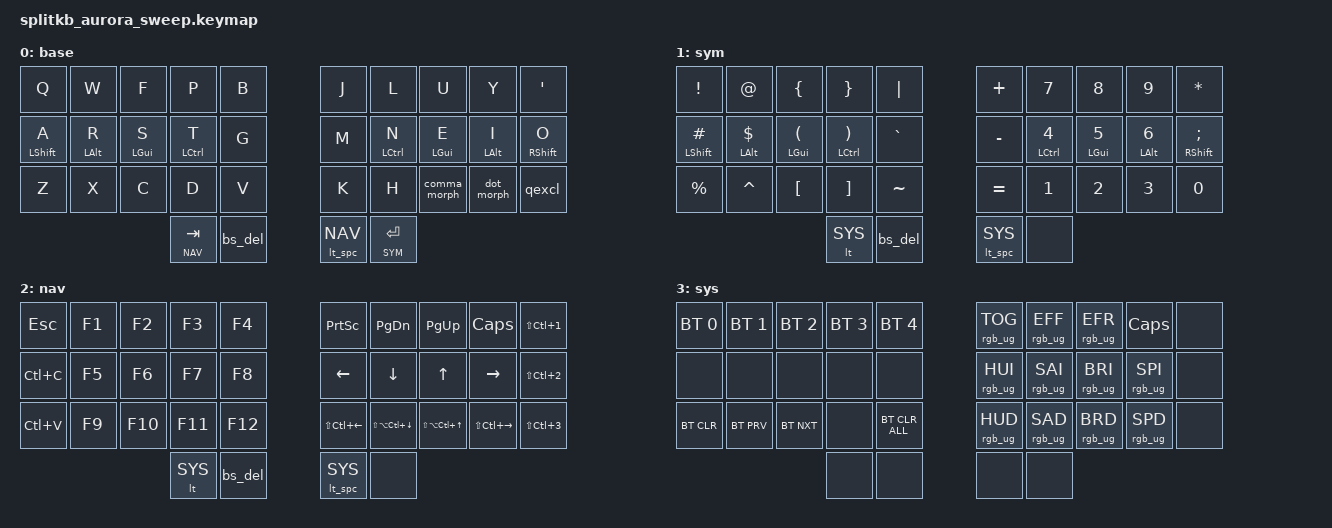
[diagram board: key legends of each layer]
#include <behaviors.dtsi>
#include <dt-bindings/zmk/bt.h>
#include <dt-bindings/zmk/keys.h>
#include <dt-bindings/zmk/rgb.h>

#include "zmk-helpers/helper.h"
#include "zmk-helpers/key-labels/34.h"

#define BASE 0
#define SYM 1
#define NAV 2
#define SYS 3

// #include "mouse.dtsi"

#define XXX &none
#define ___ &trans

#define QUICK_TAP_MS 175

&led_strip {
    chain-length = <23>;
};

&sk {  // sticky-key config
    release-after-ms = <900>;  // release after 0.6s
    quick-release;             // no double capitalization when rolling keys
};

&sl {  // sticky-layer config
    ignore-modifiers;          // allow chording sticky mods & layers
};

&lt {  // layer-tap config
    flavor = "balanced";
    tapping-term-ms = <200>;
    quick-tap-ms = <QUICK_TAP_MS>;
};

/* Homerow mods */
#define KEYS_L LT0 LT1 LT2 LT3 LT4 LM0 LM1 LM2 LM3 LM4 LB0 LB1 LB2 LB3 LB4  // left-hand keys
#define KEYS_R RT0 RT1 RT2 RT3 RT4 RM0 RM1 RM2 RM3 RM4 RB0 RB1 RB2 RB3 RB4  // right-hand keys
#define THUMBS LH1 LH0 RH0 RH1                                              // thumb keys

#define MAKE_HRM(NAME, HOLD, TAP, TRIGGER_POS) \
    ZMK_HOLD_TAP(NAME, \
        flavor = "balanced"; \
        tapping-term-ms = <280>; \
        quick-tap-ms = <QUICK_TAP_MS>; \
        require-prior-idle-ms = <150>; \
        bindings = <HOLD>, <TAP>; \
        hold-trigger-key-positions = <TRIGGER_POS>; \
        hold-trigger-on-release; \
    )

MAKE_HRM(hml, &kp, &kp, KEYS_R THUMBS)  // left-hand HRMs
MAKE_HRM(hmr, &kp, &kp, KEYS_L THUMBS)  // right-hand HRMs

/* Custom behaviors */

// reuse basic mod-morph scheme
#define SIMPLE_MORPH(NAME, MOD, BINDING1, BINDING2) \
    ZMK_MOD_MORPH(NAME, \
        mods = <(MOD_L ## MOD|MOD_R ## MOD)>; \
        bindings = <BINDING1>, <BINDING2>; \
    )

// tap: space | shift + tap: dot -> space -> sticky shift | hold: activate layer
ZMK_HOLD_TAP(lt_spc,
    flavor = "balanced";
    tapping-term-ms = <200>;
    quick-tap-ms = <QUICK_TAP_MS>;
    bindings = <&mo>, <&spc_morph>;
)
SIMPLE_MORPH(spc_morph, SFT, &kp SPACE, &dot_spc)
ZMK_MACRO(dot_spc,
    wait-ms = <0>;
    tap-ms = <5>;
    bindings = <&kp DOT &kp SPACE &sk LSHFT>;
)

// tap: comma | shift + tap: semicolon | ctrl + shift + tap: <
SIMPLE_MORPH(comma_morph, SFT, &kp COMMA, &comma_inner_morph)
SIMPLE_MORPH(comma_inner_morph, CTL, &kp SEMICOLON, &kp LESS_THAN)

// tap: dot | shift + tap: colon | ctrl + shift + tap: >
SIMPLE_MORPH(dot_morph, SFT, &kp DOT, &dot_inner_morph)
SIMPLE_MORPH(dot_inner_morph, CTL, &kp COLON, &kp GREATER_THAN)

// tap: qmark | shift + tap: excl
SIMPLE_MORPH(qexcl, SFT, &kp QMARK, &kp EXCL)

// // tap: copy | double-tap: cut
// ZMK_TAP_DANCE(copy_cut, tap_dance,
//     tapping-term-ms = <200>;
//     bindings = <&kp LC(INS)>, <&kp LC(X)>;
// )

// tap: backspace | lshft + tap: delete | rshft + tap: shift-delete
ZMK_MOD_MORPH(bs_del,
    bindings = <&kp BSPC>, <&kp DEL>;
    mods = <(MOD_LSFT|MOD_RSFT)>;
    keep-mods = <MOD_RSFT>;
)

// Keybind aliases
#define MOVETO_1 &kp LS(LC(N1))
#define MOVETO_2 &kp LS(LC(N2))
#define MOVETO_3 &kp LS(LC(N3))

#define TERM_LEFT   &kp LS(LC(LEFT))
#define TERM_RIGHT   &kp LS(LC(RIGHT))

#define WRKSPC_DN &kp LS(LA(LC(DOWN)))
#define WRKSPC_UP &kp LS(LA(LC(UP)))

ZMK_LAYER(base,
//╭─────────────┬─────────────┬─────────────┬─────────────┬─────────────╮ ╭─────────────┬─────────────┬─────────────┬─────────────┬─────────────╮
    &kp Q         &kp W         &kp F         &kp P         &kp B           &kp J         &kp L         &kp U         &kp Y         &kp SQT
//├─────────────┼─────────────┼─────────────┼─────────────┼─────────────┤ ├─────────────┼─────────────┼─────────────┼─────────────┼─────────────┤
    &hml LSHFT A    &hml LALT R     &hml LGUI S     &hml LCTRL T     &kp G           &kp M         &hmr LCTRL N     &hmr LGUI  E    &hmr LALT I &hmr RSHFT O
//├─────────────┼─────────────┼─────────────┼─────────────┼─────────────┤ ├─────────────┼─────────────┼─────────────┼─────────────┼─────────────┤
    &kp Z         &kp X         &kp C         &kp D         &kp V           &kp K         &kp H         &comma_morph  &dot_morph    &qexcl
//╰─────────────┼─────────────┴─────────────┼─────────────┼─────────────┤ ├─────────────┼─────────────┼─────────────┴───────────────────────────╯
                                              &lt NAV TAB   &bs_del         &lt_spc NAV   &lt SYM RET
//                                          ╰─────────────┴─────────────╯ ╰─────────────┴─────────────╯
)

ZMK_LAYER(sym,
//╭─────────────┬─────────────┬─────────────┬─────────────┬─────────────╮ ╭─────────────┬─────────────┬─────────────┬─────────────┬─────────────╮
    &kp EXCL      &kp AT_SIGN &kp LEFT_BRACE &kp RIGHT_BRACE &kp PIPE       &kp PLUS      &kp N7        &kp N8        &kp N9        &kp ASTERISK
//├─────────────┼─────────────┼─────────────┼─────────────┼─────────────┤ ├─────────────┼─────────────┼─────────────┼─────────────┼─────────────┤
    &hml LSHFT HASH &hml LALT DOLLAR &hml LGUI LPAR &hml LCTRL RPAR  &kp GRAVE  &kp MINUS &hmr LCTRL N4  &hmr LGUI N5    &hmr LALT N6    &hmr RSHFT SEMICOLON
//├─────────────┼─────────────┼─────────────┼─────────────┼─────────────┤ ├─────────────┼─────────────┼─────────────┼─────────────┼─────────────┤
    &kp PERCENT   &kp CARET   &kp LEFT_BRACKET &kp RIGHT_BRACKET &kp TILDE  &kp EQUAL     &kp N1        &kp N2        &kp N3        &kp N0
//╰─────────────┼─────────────┴─────────────┼─────────────┼─────────────┤ ├─────────────┼─────────────┼─────────────┴───────────────────────────╯
                                              &lt SYS       &bs_del         &lt_spc SYS   XXX
//                                          ╰─────────────┴─────────────╯ ╰─────────────┴─────────────╯
)

ZMK_LAYER(nav,
//╭─────────────┬─────────────┬─────────────┬─────────────┬─────────────╮ ╭─────────────┬─────────────┬─────────────┬─────────────┬─────────────╮
    &kp ESC       &kp F1         &kp F2       &kp F3        &kp F4        &kp PRINTSCREEN &kp PAGE_DOWN &kp PAGE_UP   &kp CAPSLOCK  MOVETO_1
//├─────────────┼─────────────┼─────────────┼─────────────┼─────────────┤ ├─────────────┼─────────────┼─────────────┼─────────────┼─────────────┤
    &kp LC(C)     &kp F5         &kp F6       &kp F7        &kp F8          &kp LEFT      &kp DOWN      &kp UP        &kp RIGHT     MOVETO_2
//├─────────────┼─────────────┼─────────────┼─────────────┼─────────────┤ ├─────────────┼─────────────┼─────────────┼─────────────┼─────────────┤
    &kp LC(V)     &kp F9         &kp F10      &kp F11       &kp F12         TERM_LEFT     WRKSPC_DN     WRKSPC_UP     TERM_RIGHT    MOVETO_3
//╰─────────────┼─────────────┴─────────────┼─────────────┼─────────────┤ ├─────────────┼─────────────┼─────────────┴───────────────────────────╯
                                              &lt SYS       &bs_del         &lt_spc SYS   XXX
//                                          ╰─────────────┴─────────────╯ ╰─────────────┴─────────────╯
)

ZMK_LAYER(sys,
//╭─────────────┬─────────────┬─────────────┬─────────────┬─────────────╮ ╭─────────────┬─────────────┬─────────────┬─────────────┬─────────────╮
    &bt BT_SEL 0  &bt BT_SEL 1  &bt BT_SEL 2  &bt BT_SEL 3  &bt BT_SEL 4  &rgb_ug RGB_TOG &rgb_ug RGB_EFF &rgb_ug RGB_EFR &kp CAPSLOCK     XXX
//├─────────────┼─────────────┼─────────────┼─────────────┼─────────────┤ ├─────────────┼─────────────┼─────────────┼─────────────┼─────────────┤
        XXX           XXX           XXX           XXX           XXX       &rgb_ug RGB_HUI &rgb_ug RGB_SAI &rgb_ug RGB_BRI &rgb_ug RGB_SPI  XXX
//├─────────────┼─────────────┼─────────────┼─────────────┼─────────────┤ ├─────────────┼─────────────┼─────────────┼─────────────┼─────────────┤
    &bt BT_CLR    &bt BT_PRV    &bt BT_NXT        XXX      &bt BT_CLR_ALL &rgb_ug RGB_HUD &rgb_ug RGB_SAD &rgb_ug RGB_BRD &rgb_ug RGB_SPD  XXX
//╰─────────────┼─────────────┴─────────────┼─────────────┼─────────────┤ ├─────────────┼─────────────┼─────────────┴───────────────────────────╯
                                                  XXX           XXX            XXX            XXX
//                                          ╰─────────────┴─────────────╯ ╰─────────────┴─────────────╯
)

ZMK_COMBO(esc, &kp ESC, LT3 LT2, BASE SYM NAV, 18, 150)

/* vim: set ft=c tw=174: */
